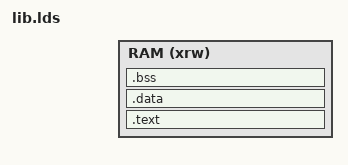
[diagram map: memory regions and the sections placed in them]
/* lib.lds - linker script for the fwsiglib ed25519 verify library.
 *
 * This file is preprocessed (`cc -E -P -x c`, see fpga/Makefile) before
 * linking: the bare ld preprocessor does not support #define. Do not
 * start any comment line with '#'.
 *
 * The library is a flat RWX blob loaded by the boot ROM at a fixed
 * address in the SPRAM (memmap.h; the -D flags are generated by
 * rom/tools/make_lib_inc.py); LMA == VMA (no PIC, no relocations - the ROM
 * copies it byte-for-byte and the trampoline in rom/libcall.S jumps to
 * its absolute address).
 *
 * Loaded to [FK_LIB_BASE, FK_STACK_REGION_BASE) (currently [0x17800,
 * 0x1E000)), between the firmware image (which must end by FK_LIB_BASE,
 * enforced by firmware/support/sections.lds) and the ROM/firmware stack
 * (which starts at FK_STACK_TOP and may use the gap above the library).
 *
 * This library is linked with --gc-sections, so only the verify path
 * is included in the final binary. Resulting size is ~23 kB.
 *
 * The library must not use .bss: nothing in this system zeroes it for
 * the library (checked by the build).
 */
#include "../../memmap.h"

MEMORY {
    RAM (xrw) : ORIGIN = FK_LIB_BASE, LENGTH = FK_FLIB_SLOT_SIZE
}

ENTRY(fk_lib_verify)

SECTIONS {
    .text :
    {
        _ltext = .;
        *(.text)
        *(.text*)
        *(.rodata)
        *(.rodata*)
        *(.srodata)
        *(.srodata*)
        . = ALIGN(4);
        _ltext_end = .;
    } >RAM

    .data :
    {
        . = ALIGN(4);
        _sdata = .;
        *(.data)
        *(.data*)
        *(.sdata)
        *(.sdata*)
        . = ALIGN(4);
        _edata = .;
    } >RAM

    .bss (NOLOAD) :
    {
        _sbss = .;
        *(.bss)
        *(.bss*)
        *(.sbss)
        *(.sbss*)
        *(COMMON)
        . = ALIGN(4);
        _ebss = .;
    } >RAM

    _lend = .;
}
